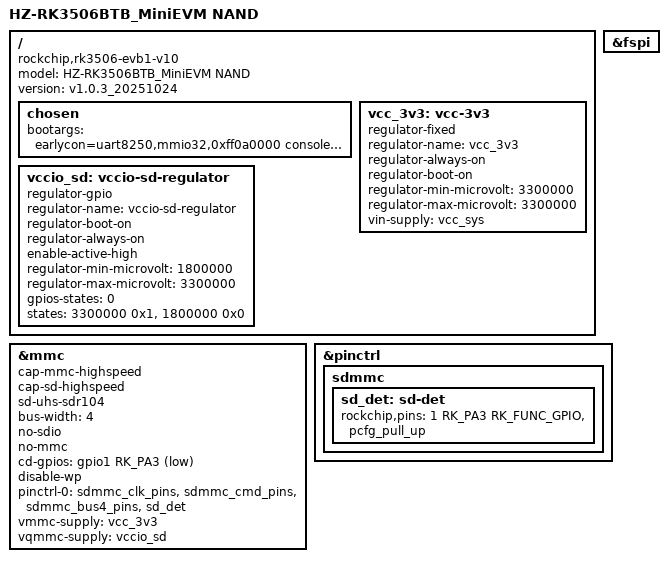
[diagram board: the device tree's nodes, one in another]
// SPDX-License-Identifier: (GPL-2.0+ OR MIT)
/*
* Copyright (c) 2025 HZHY Electronics Co., Ltd.
*/

/dts-v1/;

#include "HZ-RK3506_MiniEVM.dtsi"
// #include "HZ-RK3506_MiniEVM_HDMI.dtsi"
#include "HZ-RK3506_MiniEVM_MIPI.dtsi"

/ {
	model = "HZ-RK3506BTB_MiniEVM NAND";
	compatible = "rockchip,rk3506-evb1-v10", "rockchip,rk3506";
	version = "v1.0.3_20251024";
	chosen {
		// bootargs = "earlycon=uart8250,mmio32,0xff0a0000 console=ttyFIQ0 ubi.mtd=7 ubi.block=0,rootfs root=/dev/ubiblock0_0 rootfstype=squashfs rootwait snd_aloop.index=7 snd_aloop.use_raw_jiffies=1 storagemedia=mtd androidboot.storagemedia=mtd androidboot.mode=normal";
		//bootargs = "earlycon=uart8250,mmio32,0xff0a0000 console=ttyFIQ0 ubi.mtd=5 ubi.block=0,rootfs root=/dev/ubiblock0_0 rootfstype=squashfs rootwait snd_aloop.index=7 snd_aloop.use_raw_jiffies=1 storagemedia=mtd androidboot.storagemedia=mtd androidboot.mode=normal";
		bootargs = "earlycon=uart8250,mmio32,0xff0a0000 console=ttyFIQ0 ubi.mtd=5 root=ubi0:rootfs rw rootfstype=ubifs rootwait snd_aloop.index=7 snd_aloop.use_raw_jiffies=1";
		// bootargs = "earlycon=uart8250,mmio32,0xff0a0000 console=ttyFIQ0 ubi.mtd=5 ubi.block=0,rootfs root=ubi0:rootfs rootfstype=ubifs rootwait snd_aloop.index=7 snd_aloop.use_raw_jiffies=1 storagemedia=mtd androidboot.storagemedia=mtd androidboot.mode=normal";
		// bootargs = "earlycon=uart8250,mmio32,0xff0a0000 console=ttyFIQ0 ubi.mtd=5 root=ubi0:rootfs rw rootfstype=ubifs rootwait snd_aloop.index=7 snd_aloop.use_raw_jiffies=1";
		// bootargs = "earlycon=uart8250,mmio32,0xff0a0000 console=ttyFIQ0 ubi.mtd=7 root=/dev/ubiblock0_0 rw rootfstype=ubifs rootwait snd_aloop.index=7 snd_aloop.use_raw_jiffies=1";
	};
	/delete-node/ sdio-pwrseq;
	
	vcc_3v3: vcc-3v3 {
		compatible = "regulator-fixed";
		regulator-name = "vcc_3v3";
		regulator-always-on;
		regulator-boot-on;
		regulator-min-microvolt = <3300000>;
		regulator-max-microvolt = <3300000>;
		vin-supply = <&vcc_sys>;
	};
	
	vccio_sd: vccio-sd-regulator  {
		compatible = "regulator-gpio";
		regulator-name = "vccio-sd-regulator";
		//gpios = <&gpio4 RK_PB2 GPIO_ACTIVE_HIGH>;
		regulator-boot-on;
		regulator-always-on;
		enable-active-high;
		regulator-min-microvolt = <1800000>;
		regulator-max-microvolt = <3300000>;
		// startup-delay-us = <20000>;
		gpios-states = <0>;
		states = <3300000 0x1>,
		<1800000 0x0>;
	};
};

&fspi {
	status = "okay";
};

&mmc {
	/* For SDMMC */
	/delete-property/ no-sd;
	/delete-property/ ignore-pm-notify;
	/delete-property/ keep-power-in-suspend;
	/delete-property/ non-removable;
	/delete-property/ mmc-pwrseq;
	cap-mmc-highspeed;
	cap-sd-highspeed;
	sd-uhs-sdr104;
	bus-width = <4>;
	no-sdio;
	no-mmc;
	cd-gpios = <&gpio1 RK_PA3 GPIO_ACTIVE_LOW>;
	disable-wp;
	pinctrl-names = "default";
	pinctrl-0 = <&sdmmc_clk_pins &sdmmc_cmd_pins &sdmmc_bus4_pins &sd_det>;
	vmmc-supply = <&vcc_3v3>;
	vqmmc-supply = <&vccio_sd>;
	status = "okay";
};


&pinctrl {
	
	sdmmc {
		sd_det: sd-det {
			rockchip,pins = <1 RK_PA3 RK_FUNC_GPIO &pcfg_pull_up>;
		};
	};
};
